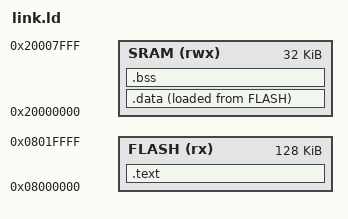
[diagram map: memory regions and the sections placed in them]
/* Minimal linker script for GD32VF103 snippet harness.
 * Memory map matches GD32VF103CB (128 KiB Flash, 32 KiB SRAM). */

ENTRY(_start)

MEMORY
{
    FLASH (rx) : ORIGIN = 0x08000000, LENGTH = 128K
    SRAM  (rwx): ORIGIN = 0x20000000, LENGTH = 32K
}

_estack = ORIGIN(SRAM) + LENGTH(SRAM);

SECTIONS
{
    .text : {
        KEEP(*(.text._start))
        *(.text*)
        *(.rodata*)
    } > FLASH

    .data : {
        _sdata = .;
        *(.data*)
        *(.sdata*)
        _edata = .;
    } > SRAM AT > FLASH

    .bss : {
        _sbss = .;
        *(.bss*)
        *(.sbss*)
        *(COMMON)
        _ebss = .;
    } > SRAM
}
